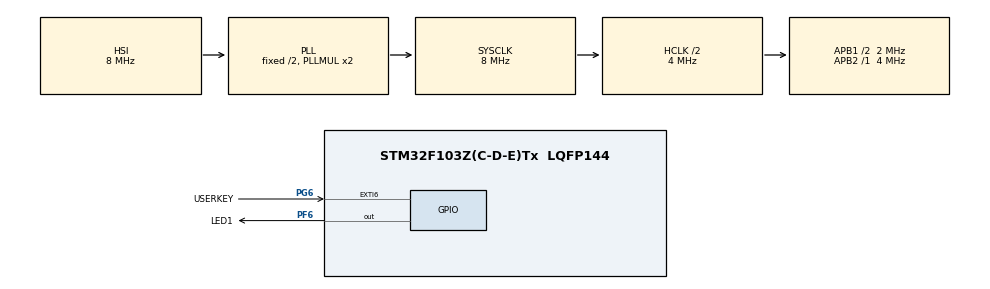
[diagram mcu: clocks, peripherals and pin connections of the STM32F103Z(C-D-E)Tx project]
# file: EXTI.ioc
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Mcu.Family=STM32F1
Mcu.Name=STM32F103Z(C-D-E)Tx
Mcu.Package=LQFP144
NVIC.EXTI9_5_IRQn=true\:1\:0\:true\:false\:true
NVIC.PriorityGroup=NVIC_PRIORITYGROUP_4
PF6.GPIO_Label=LED1
PF6.Signal=GPIO_Output
PG6.GPIO_Label=USERKEY
PG6.GPIO_ModeDefaultEXTI=GPIO_MODE_IT_FALLING
PG6.GPIO_PuPd=GPIO_PULLUP
PG6.Signal=GPXTI6
ProjectManager.HeapSize=0x200
ProjectManager.StackSize=0x400
ProjectManager.TargetToolchain=MDK-ARM V5
RCC.AHBCLKDivider=RCC_SYSCLK_DIV2
RCC.AHBFreq_Value=4000000
RCC.APB1CLKDivider=RCC_HCLK_DIV2
RCC.APB1Freq_Value=2000000
RCC.APB1TimFreq_Value=4000000
RCC.APB2Freq_Value=4000000
RCC.APB2TimFreq_Value=4000000
RCC.HCLKFreq_Value=4000000
RCC.SYSCLKFreq_VALUE=8000000
RCC.SYSCLKSource=RCC_SYSCLKSOURCE_PLLCLK
RCC.USBFreq_Value=8000000
VP_SYS_VS_ND.Mode=No_Debug
board=EXTI

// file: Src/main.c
/**
  ******************************************************************************
  * File Name          : main.c
  * Description        : Main program body
  ******************************************************************************
  *
  * COPYRIGHT(c) 2016 STMicroelectronics
  *
  * Redistribution and use in source and binary forms, with or without modification,
  * are permitted provided that the following conditions are met:
  *   1. Redistributions of source code must retain the above copyright notice,
  *      this list of conditions and the following disclaimer.
  *   2. Redistributions in binary form must reproduce the above copyright notice,
  *      this list of conditions and the following disclaimer in the documentation
  *      and/or other materials provided with the distribution.
  *   3. Neither the name of STMicroelectronics nor the names of its contributors
  *      may be used to endorse or promote products derived from this software
  *      without specific prior written permission.
  *
  * THIS SOFTWARE IS PROVIDED BY THE COPYRIGHT HOLDERS AND CONTRIBUTORS "AS IS"
  * AND ANY EXPRESS OR IMPLIED WARRANTIES, INCLUDING, BUT NOT LIMITED TO, THE
  * IMPLIED WARRANTIES OF MERCHANTABILITY AND FITNESS FOR A PARTICULAR PURPOSE ARE
  * DISCLAIMED. IN NO EVENT SHALL THE COPYRIGHT HOLDER OR CONTRIBUTORS BE LIABLE
  * FOR ANY DIRECT, INDIRECT, INCIDENTAL, SPECIAL, EXEMPLARY, OR CONSEQUENTIAL
  * DAMAGES (INCLUDING, BUT NOT LIMITED TO, PROCUREMENT OF SUBSTITUTE GOODS OR
  * SERVICES; LOSS OF USE, DATA, OR PROFITS; OR BUSINESS INTERRUPTION) HOWEVER
  * CAUSED AND ON ANY THEORY OF LIABILITY, WHETHER IN CONTRACT, STRICT LIABILITY,
  * OR TORT (INCLUDING NEGLIGENCE OR OTHERWISE) ARISING IN ANY WAY OUT OF THE USE
  * OF THIS SOFTWARE, EVEN IF ADVISED OF THE POSSIBILITY OF SUCH DAMAGE.
  *
  ******************************************************************************
  */
#include "main.h"
#include "stm32f1xx_hal.h"
#include "gpio.h"

/* USER CODE BEGIN PV */
/* Private variables ---------------------------------------------------------*/

/* USER CODE END PV */

void SystemClock_Config(void);
void Error_Handler(void);

/* USER CODE BEGIN PFP */
/* Private function prototypes -----------------------------------------------*/

/* USER CODE END PFP */

int main(void)
{

  /* MCU Configuration----------------------------------------------------------*/

  /* Reset of all peripherals, Initializes the Flash interface and the Systick. */
  HAL_Init();

  /* Configure the system clock */
  SystemClock_Config();

  /* Initialize all configured peripherals */
  MX_GPIO_Init();

  /* Infinite loop */
  while (1)
  {

  }

}

/** System Clock Configuration
*/
void SystemClock_Config(void)
{

  RCC_OscInitTypeDef RCC_OscInitStruct;
  RCC_ClkInitTypeDef RCC_ClkInitStruct;

    /**Initializes the CPU, AHB and APB busses clocks
    */
  RCC_OscInitStruct.OscillatorType = RCC_OSCILLATORTYPE_HSI;
  RCC_OscInitStruct.HSIState = RCC_HSI_ON;
  RCC_OscInitStruct.HSICalibrationValue = 16;
  RCC_OscInitStruct.PLL.PLLState = RCC_PLL_ON;
  RCC_OscInitStruct.PLL.PLLSource = RCC_PLLSOURCE_HSI_DIV2;
  RCC_OscInitStruct.PLL.PLLMUL = RCC_PLL_MUL2;
  if (HAL_RCC_OscConfig(&RCC_OscInitStruct) != HAL_OK)
  {
    Error_Handler();
  }

    /**Initializes the CPU, AHB and APB busses clocks
    */
  RCC_ClkInitStruct.ClockType = RCC_CLOCKTYPE_HCLK|RCC_CLOCKTYPE_SYSCLK
                              |RCC_CLOCKTYPE_PCLK1|RCC_CLOCKTYPE_PCLK2;
  RCC_ClkInitStruct.SYSCLKSource = RCC_SYSCLKSOURCE_PLLCLK;
  RCC_ClkInitStruct.AHBCLKDivider = RCC_SYSCLK_DIV2;
  RCC_ClkInitStruct.APB1CLKDivider = RCC_HCLK_DIV2;
  RCC_ClkInitStruct.APB2CLKDivider = RCC_HCLK_DIV1;

  if (HAL_RCC_ClockConfig(&RCC_ClkInitStruct, FLASH_LATENCY_0) != HAL_OK)
  {
    Error_Handler();
  }

    /**Configure the Systick interrupt time
    */
  HAL_SYSTICK_Config(HAL_RCC_GetHCLKFreq()/1000);

    /**Configure the Systick
    */
  HAL_SYSTICK_CLKSourceConfig(SYSTICK_CLKSOURCE_HCLK);

  /* SysTick_IRQn interrupt configuration */
  HAL_NVIC_SetPriority(SysTick_IRQn, 0, 0);
}

/* USER CODE BEGIN 4 */
/**
  * @brief  EXTI line detection callbacks
  * @param  GPIO_Pin: Specifies the pins connected EXTI line
  * @retval None
  */
void HAL_GPIO_EXTI_Callback(uint16_t GPIO_Pin)
{
  /* Press USER KEY (PG6, i.e. GPIO_EXTI6) to toggle LED1. */
  if((HAL_GPIO_ReadPin(USERKEY_GPIO_Port, USERKEY_Pin) == GPIO_PIN_RESET) && (GPIO_Pin == USERKEY_Pin))
  {
    /* Toggle LED1 */
    HAL_GPIO_TogglePin(LED1_GPIO_Port, LED1_Pin);

    /** This prevents the USER KEY from inadvertently touch.
      * To use HAL_Delay function,
      * NVIC priority of EXTI interrupts must be lower than System tick timer.
      * See: NVIC Configuration in STM32CubeMX (Higher number has lower priority). */
    HAL_Delay(200);
  }
}
/* USER CODE END 4 */

void Error_Handler(void)
{
  while(1)
  {
  }
}

/************************ (C) COPYRIGHT STMicroelectronics *****END OF FILE****/
